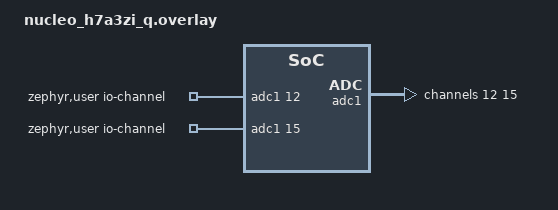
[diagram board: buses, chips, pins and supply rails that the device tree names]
/*
 * SPDX-License-Identifier: Apache-2.0
 *
 * Copyright (c) Benjamin Björnsson <benjamin.bjornsson@gmail.com>
 */

/ {
	zephyr,user {
		/* adjust channel number according to pinmux in board.dts */
		io-channels = <&adc1 12>, <&adc1 15>;
	};
};

&adc1 {
	#address-cells = <1>;
	#size-cells = <0>;

	channel@c {
		reg = <12>;
		zephyr,gain = "ADC_GAIN_1";
		zephyr,reference = "ADC_REF_INTERNAL";
		zephyr,acquisition-time = <ADC_ACQ_TIME_DEFAULT>;
		zephyr,resolution = <16>;
	};

	channel@f {
		reg = <15>;
		zephyr,gain = "ADC_GAIN_1";
		zephyr,reference = "ADC_REF_INTERNAL";
		zephyr,acquisition-time = <ADC_ACQ_TIME_DEFAULT>;
		zephyr,resolution = <16>;
	};
};
